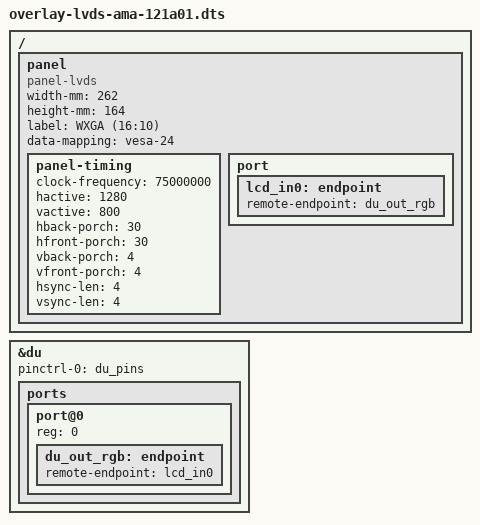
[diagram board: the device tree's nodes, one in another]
/*
 * Copyright (C) 2022 Avnet Embedded GmbH
 *
 * This program is free software; you can redistribute it and/or
 * modify it under the terms of the GNU General Public License as
 * published by the Free Software Foundation version 2.
 *
 * This program is distributed "as is" WITHOUT ANY WARRANTY of any
 * kind, whether express or implied; without even the implied warranty
 * of MERCHANTABILITY or FITNESS FOR A PARTICULAR PURPOSE.  See the
 * GNU General Public License for more details.
 */

/dts-v1/;
/plugin/;


/ {
       fragment@4000 {
               target-path = "/";
               __overlay__ {
                       panel {
                                compatible = "panel-lvds";
                		width-mm = <262>;
                		height-mm = <164>;
                		label = "WXGA (16:10)";
                		data-mapping = "vesa-24";
                		status = "okay";

                		panel-timing {
                		        clock-frequency = <75000000>;
                		        hactive = <1280>;
                		        vactive = <800>;
                		        hback-porch = <30>;
                		        hfront-porch = <30>;
                		        vback-porch = <4>;
                		        vfront-porch = <4>;
                		        hsync-len = <4>;
                		        vsync-len = <4>;
                		};

                		port {
                		    lcd_in0: endpoint {
                		            remote-endpoint = <&du_out_rgb>;
                		    };
                		};
                       };
               };
       };

	fragment@4001 {
                target = <&du>;
                __overlay__ {
                        pinctrl-0 = <&du_pins>;
                        pinctrl-names = "default";
                        status = "okay";

                        ports {
                                port@0 {
                                        reg = <0>;
                                        du_out_rgb: endpoint {
                                                remote-endpoint = <&lcd_in0>;
                                        };
                                };
                        };
                };
        };
};

